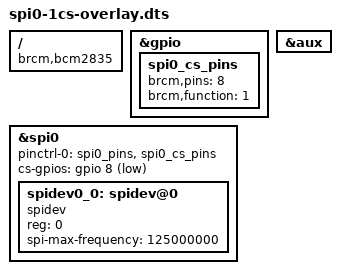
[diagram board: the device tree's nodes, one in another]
/dts-v1/;
/plugin/;


/ {
	compatible = "brcm,bcm2835", "brcm,bcm2836", "brcm,bcm2708", "brcm,bcm2709";

	fragment@0 {
		target = <&gpio>;
		__overlay__ {
			spi0_cs_pins: spi0_cs_pins {
				brcm,pins = <8>;
				brcm,function = <1>; /* output */
			};
		};
	};

	fragment@1 {
		target = <&spi0>;
		frag1: __overlay__ {
			/* needed to avoid dtc warning */
			#address-cells = <1>;
			#size-cells = <0>;
			pinctrl-names = "default";
			pinctrl-0 = <&spi0_pins &spi0_cs_pins>;
			cs-gpios = <&gpio 8 1>;
			status = "okay";

			spidev0_0: spidev@0 {
				compatible = "spidev";
				reg = <0>;      /* CE0 */
				#address-cells = <1>;
				#size-cells = <0>;
				spi-max-frequency = <125000000>;
				status = "okay";
			};
		};
	};

	fragment@2 {
		target = <&aux>;
		__overlay__ {
			status = "okay";
		};
	};

	__overrides__ {
		cs0_pin  = <&spi0_cs_pins>,"brcm,pins:0", <&frag1>,"cs-gpios:4";
		cs0_spidev = <&spidev0_0>,"status";
	};
};
